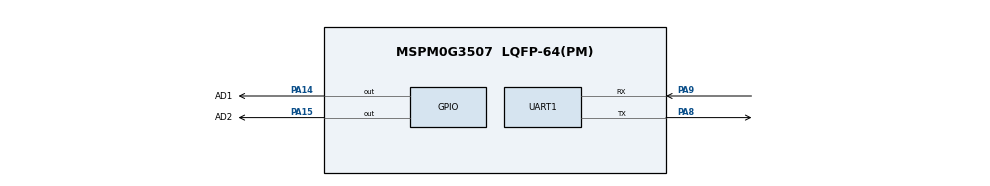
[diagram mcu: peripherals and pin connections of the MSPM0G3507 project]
/**
 * These arguments were used when this file was generated. They will be automatically applied on subsequent loads
 * via the GUI or CLI. Run CLI with '--help' for additional information on how to override these arguments.
 * @cliArgs --device "MSPM0G350X" --part "Default" --package "LQFP-64(PM)" --product "mspm0_sdk@2.05.01.00"
 * @v2CliArgs --device "MSPM0G3507" --package "LQFP-64(PM)" --product "mspm0_sdk@2.05.01.00"
 * @versions {"tool":"1.24.0+4110"}
 */

/**
 * Import the modules used in this configuration.
 */
const ADC12  = scripting.addModule("/ti/driverlib/ADC12", {}, false);
const ADC121 = ADC12.addInstance();
const Board  = scripting.addModule("/ti/driverlib/Board");
const GPIO   = scripting.addModule("/ti/driverlib/GPIO", {}, false);
const GPIO1  = GPIO.addInstance();
const SYSCTL = scripting.addModule("/ti/driverlib/SYSCTL");
const UART   = scripting.addModule("/ti/driverlib/UART", {}, false);
const UART1  = UART.addInstance();

/**
 * Write custom configuration values to the imported modules.
 */
ADC121.$name               = "OUT";
ADC121.adcMem0trig         = "DL_ADC12_TRIGGER_MODE_TRIGGER_NEXT";
ADC121.sampClkDiv          = "DL_ADC12_CLOCK_DIVIDE_8";
ADC121.powerDownMode       = "DL_ADC12_POWER_DOWN_MODE_MANUAL";
ADC121.sampleTime0         = "125us";
ADC121.adcPin0Config.$name = "ti_driverlib_gpio_GPIOPinGeneric2";


GPIO1.port                          = "PORTA";
GPIO1.$name                         = "TRACE";
GPIO1.associatedPins.create(3);
GPIO1.associatedPins[0].$name       = "AD0";
GPIO1.associatedPins[0].assignedPin = "13";
GPIO1.associatedPins[1].$name       = "AD1";
GPIO1.associatedPins[1].assignedPin = "14";
GPIO1.associatedPins[1].pin.$assign = "PA14";
GPIO1.associatedPins[2].$name       = "AD2";
GPIO1.associatedPins[2].assignedPin = "15";
GPIO1.associatedPins[2].pin.$assign = "PA15";

SYSCTL.forceDefaultClkConfig = true;

UART1.$name                            = "TRACE_UART";
UART1.enableFIFO                       = true;
UART1.enableDMARX                      = false;
UART1.enableDMATX                      = false;
UART1.rxFifoThreshold                  = "DL_UART_RX_FIFO_LEVEL_3_4_FULL";
UART1.rxTimeoutValue                   = 15;
UART1.txPinConfig.direction            = scripting.forceWrite("OUTPUT");
UART1.txPinConfig.hideOutputInversion  = scripting.forceWrite(false);
UART1.txPinConfig.onlyInternalResistor = scripting.forceWrite(false);
UART1.txPinConfig.passedPeripheralType = scripting.forceWrite("Digital");
UART1.txPinConfig.$name                = "ti_driverlib_gpio_GPIOPinGeneric0";
UART1.rxPinConfig.hideOutputInversion  = scripting.forceWrite(false);
UART1.rxPinConfig.onlyInternalResistor = scripting.forceWrite(false);
UART1.rxPinConfig.passedPeripheralType = scripting.forceWrite("Digital");
UART1.rxPinConfig.$name                = "ti_driverlib_gpio_GPIOPinGeneric1";
UART1.peripheral.rxPin.$assign         = "PA9";
UART1.peripheral.txPin.$assign         = "PA8";

/**
 * Pinmux solution for unlocked pins/peripherals. This ensures that minor changes to the automatic solver in a future
 * version of the tool will not impact the pinmux you originally saw.  These lines can be completely deleted in order to
 * re-solve from scratch.
 */
ADC121.peripheral.$suggestSolution           = "ADC0";
ADC121.peripheral.adcPin0.$suggestSolution   = "PA27";
Board.peripheral.$suggestSolution            = "DEBUGSS";
Board.peripheral.swclkPin.$suggestSolution   = "PA20";
Board.peripheral.swdioPin.$suggestSolution   = "PA19";
GPIO1.associatedPins[0].pin.$suggestSolution = "PA13";
SYSCTL.peripheral.$suggestSolution           = "SYSCTL";
UART1.peripheral.$suggestSolution            = "UART1";
